# R7FA2E1A9 register map
Vendor: Renesas Electronics Corporation; Series: RA2; File version: 0.60.01
CPU: CM23 r1p0, little endian, MPU, no FPU, VTOR, 2 interrupt priority bits, 32 interrupts
Registers are 8-bit, read-write, reset 0x0 unless marked. A register's access mark holds for its fields unless they carry their own. Offsets are from the block's base; [hi:lo] are bit positions; {n}, {i} and the like mark numbered series; 'fields as' and 'values as' point back to an identical list.

## SRAM — SRAM Control
Base 0x40002000
0x00 PARIOAD — SRAM Parity Error Operation After Detection Register
  [0] OAD — Operation After Detection
    0=Non-maskable interrupt; 1=Reset
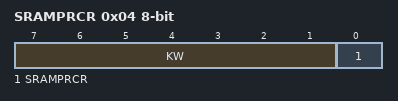
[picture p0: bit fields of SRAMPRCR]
0x04 SRAMPRCR — SRAM Protection Register
  [7:1] KW wo — Write Key Code
  [0] SRAMPRCR — Register Write Control
    0=Disable writes to protected registers; 1=Enable writes to protected registers

## BUS — BUS Control
Base 0x40003000
0x1008 BUSMCNTSYS 16-bit — Master Bus Control Register SYS
  [15] IERES — Ignore Error Responses
    0=A bus error is reported; 1=A bus error is not reported
0x100C BUSMCNTDMA 16-bit — Master Bus Control Register DMA
  fields as BUSMCNTSYS
0x1820 BUS3ERRADD 32-bit ro reset not defined — Bus Error Address Register 3
  [31:0] BERAD — Bus Error Address
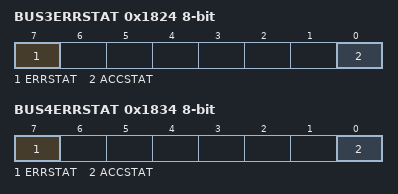
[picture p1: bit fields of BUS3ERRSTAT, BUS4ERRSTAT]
0x1824 BUS3ERRSTAT ro (reset mask 0xFE) — BUS Error Status Register 3
  [7] ERRSTAT — Bus Error Status
    0=No bus error occurred; 1=Bus error occurred
  [0] ACCSTAT — Error Access Status
    0=Read access; 1=Write access
0x1830 BUS4ERRADD 32-bit ro reset not defined — Bus Error Address Register 4
  [31:0] BERAD — Bus Error Address
0x1834 BUS4ERRSTAT ro (reset mask 0xFE) — BUS Error Status Register 4
  fields as BUS3ERRSTAT

## DTC — Data Transfer Controller
Base 0x40005400
0x00 DTCCR reset 0x8 — DTC Control Register
  [4] RRS — DTC Transfer Information Read Skip Enable
    0=Transfer information read is not skipped; 1=Transfer information read is skipped when vector numbers match
0x04 DTCVBR 32-bit — DTC Vector Base Register
0x0C DTCST — DTC Module Start Register
  [0] DTCST — DTC Module Start
    0=DTC module stopped; 1=DTC module started
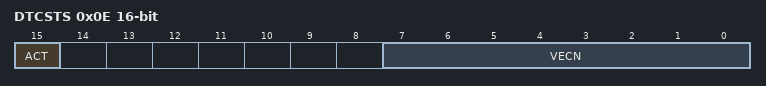
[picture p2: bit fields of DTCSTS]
0x0E DTCSTS 16-bit ro — DTC Status Register
  [15] ACT — DTC Active Flag
    0=DTC transfer operation is not in progress; 1=DTC transfer operation is in progress
  [7:0] VECN — DTC-Activating Vector Number Monitoring

## DBG — Debug Function
Base 0x4001B000
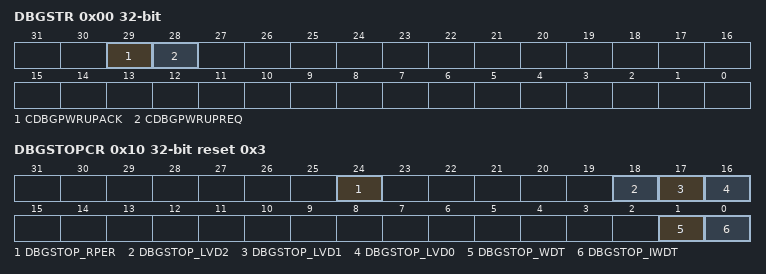
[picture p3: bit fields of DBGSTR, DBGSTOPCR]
0x00 DBGSTR 32-bit ro — Debug Status Register
  [29] CDBGPWRUPACK — Debug power-up acknowledge
    0=Debug power-up request is not acknowledged; 1=Debug power-up request is acknowledged
  [28] CDBGPWRUPREQ — Debug power-up request
    0=OCD is not requesting debug power up; 1=OCD is requesting debug power up
0x10 DBGSTOPCR 32-bit reset 0x3 — Debug Stop Control Register
  [24] DBGSTOP_RPER — Mask bit for SRAM parity error reset/interrupt
    0=Enable SRAM parity error reset/interrupt; 1=Mask SRAM parity error reset/interrupt
  [18] DBGSTOP_LVD2 — Mask bit for LVD2 reset/interrupt
    0=Enable LVD2 reset/interrupt; 1=Mask LVD2 reset/interrupt
  [17] DBGSTOP_LVD1 — Mask bit for LVD1 reset/interrupt
    0=Enable LVD1 reset/interrupt; 1=Mask LVD1 reset/interrupt
  [16] DBGSTOP_LVD0 — Mask bit for LVD0 reset
    0=Enable LVD0 reset; 1=Mask LVD0 reset
  [1] DBGSTOP_WDT — Mask bit for WDT reset/interrupt
    0=Enable WDT reset/interrupt; 1=Mask WDT reset/interrupt and stop WDT count when CPU is in OCD break mode
  [0] DBGSTOP_IWDT — Mask bit for IWDT reset/interrupt
    0=Enable IWDT reset/interrupt; 1=Mask IWDT reset/interrupt and stop IWDT count when CPU is in OCD break mode

## PORT0 — Port 0 Control Registers
Base 0x40040000
Same registers: PORT3 0x40040060, PORT4 0x40040080, PORT5 0x400400A0, PORT6 0x400400C0, PORT7 0x400400E0, PORT8 0x40040100
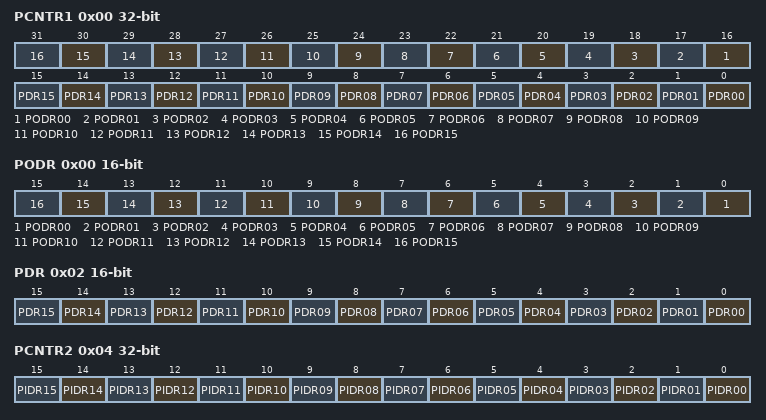
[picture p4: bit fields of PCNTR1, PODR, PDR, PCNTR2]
0x00 PCNTR1 32-bit — Port Control Register 1
  [n+16] PODR{n:02} (n=0..15) — Pmn Output Data
    0=Low output; 1=High output
  [n] PDR{n:02} (n=0..15) — Pmn Direction
    0=Input (functions as an input pin); 1=Output (functions as an output pin)
0x00 PODR 16-bit (alternate view of PCNTR1) — Port Control Register 1
  [all] fields
    0=Low output; 1=High output
  [n] PODR{n:02} (n=0..15) — Pmn Output Data
0x02 PDR 16-bit (alternate view of PCNTR1) — Port Control Register 1
  [all] fields
    values as PCNTR1.PDR00
  [n] PDR{n:02} (n=0..15) — Pmn Direction
0x04 PCNTR2 32-bit ro (reset mask 0xFFFF0000) — Port Control Register 2
  [all] fields
    0=Low level; 1=High level
  [n] PIDR{n:02} (n=0..15) — Pmn State
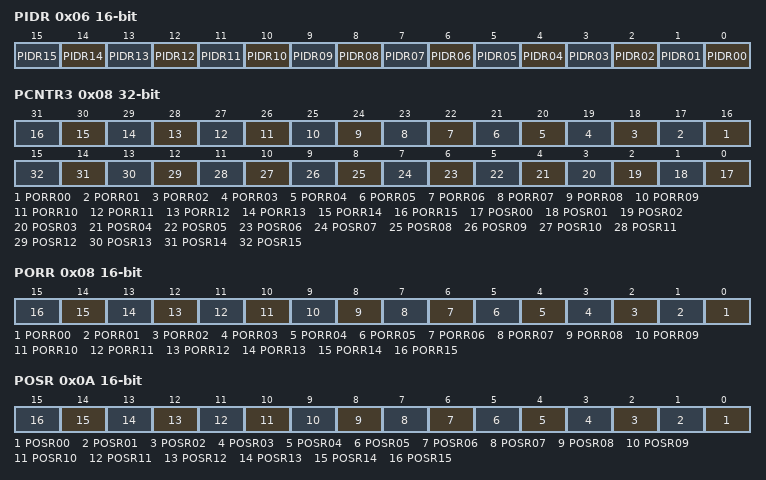
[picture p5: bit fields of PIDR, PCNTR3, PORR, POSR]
0x06 PIDR 16-bit ro reset not defined (alternate view of PCNTR2) — Port Control Register 2
  fields as PCNTR2
0x08 PCNTR3 32-bit wo — Port Control Register 3
  [n+16] PORR{n:02} (n=0..15) — Pmn Output Reset
    0=No effect on output; 1=Low output
  [n] POSR{n:02} (n=0..15) — Pmn Output Set
    0=No effect on output; 1=High output
0x08 PORR 16-bit wo (alternate view of PCNTR3) — Port Control Register 3
  [all] fields
    0=No effect on output; 1=Low output
  [n] PORR{n:02} (n=0..15) — Pmn Output Reset
0x0A POSR 16-bit wo (alternate view of PCNTR3) — Port Control Register 3
  [all] fields
    0=No effect on output; 1=High output
  [n] POSR{n:02} (n=0..15) — Pmn Output Set

## PORT1 — Port 1 Control Registers
Base 0x40040020
Same registers: PORT2 0x40040040
Registers as PORT0; these are added or differ:
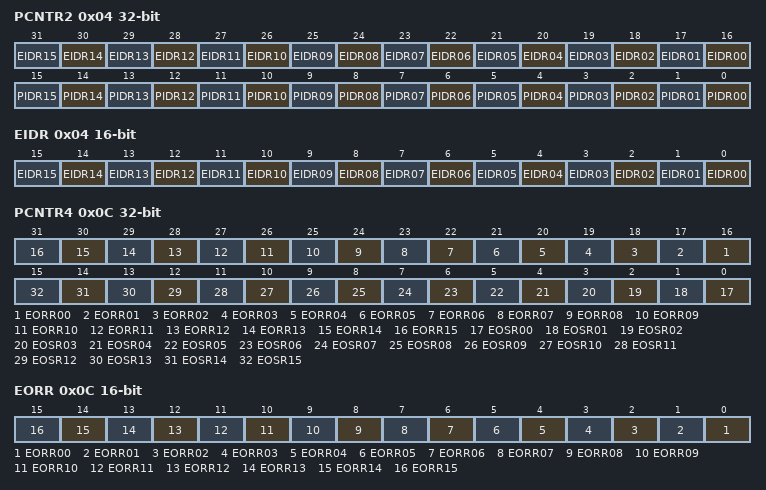
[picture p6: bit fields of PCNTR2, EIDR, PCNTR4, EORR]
0x04 PCNTR2 32-bit ro (reset mask 0xFFFF0000) — Port Control Register 2
  [n+16] EIDR{n:02} (n=0..15) — Port Event Input Data
    0=Low input; 1=High input
  [n] PIDR{n:02} (n=0..15) — Pmn State
    0=Low level; 1=High level
0x04 EIDR 16-bit ro (alternate view of PCNTR2) — Port Control Register 2
  [all] fields
    0=Low input; 1=High input
  [n] EIDR{n:02} (n=0..15) — Port Event Input Data
0x0C PCNTR4 32-bit — Port Control Register 4
  [n+16] EORR{n:02} (n=0..15) — Pmn Event Output Reset
    0=No effect on output; 1=Low output
  [n] EOSR{n:02} (n=0..15) — Pmn Event Output Set
    0=No effect on output; 1=High output
0x0C EORR 16-bit (alternate view of PCNTR4) — Port Control Register 4
  [all] fields
    0=No effect on output; 1=Low output
  [n] EORR{n:02} (n=0..15) — Pmn Event Output Reset
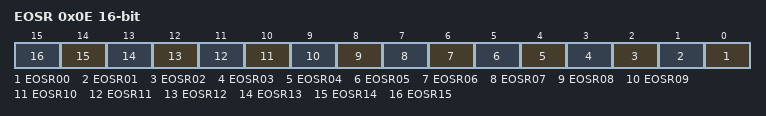
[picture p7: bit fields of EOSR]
0x0E EOSR 16-bit (alternate view of PCNTR4) — Port Control Register 4
  [all] fields
    0=No effect on output; 1=High output
  [n] EOSR{n:02} (n=0..15) — Pmn Event Output Set

## Notices in the file
This software is supplied by Renesas Electronics Corporation and is only intended for
use with Renesas products. No other uses are authorized. This software is owned by
Renesas Electronics Corporation and is protected under all applicable laws, including
copyright laws.
THIS SOFTWARE IS PROVIDED "AS IS" AND RENESAS MAKES NO WARRANTIES REGARDING
THIS SOFTWARE, WHETHER EXPRESS, IMPLIED OR STATUTORY, INCLUDING BUT NOT LIMITED TO
WARRANTIES OF MERCHANTABILITY, FITNESS FOR A PARTICULAR PURPOSE AND NON-INFRINGEMENT.
ALL SUCH WARRANTIES ARE EXPRESSLY DISCLAIMED. TO THE MAXIMUM EXTENT PERMITTED NOT
PROHIBITED BY LAW, NEITHER RENESAS ELECTRONICS CORPORATION NOR ANY OF ITS AFFILIATED
COMPANIES SHALL BE LIABLE FOR ANY DIRECT, INDIRECT, SPECIAL, INCIDENTAL OR CONSEQUENTIAL
DAMAGES FOR ANY REASON RELATED TO THIS SOFTWARE, EVEN IF RENESAS OR ITS AFFILIATES HAVE
BEEN ADVISED OF THE POSSIBILITY OF SUCH DAMAGES.
Renesas reserves the right, without notice, to make changes to this software and to
discontinue the availability of this software. By using this software, you agree to
the additional terms and conditions found by accessing the following link:
http://www.renesas.com/disclaimer
